# ATmega128 device description
Architecture: AVR8; Family: megaAVR
Registers are 8-bit, access not given, no defined reset value unless marked. A register's access mark holds for its fields unless they carry their own. Offsets are from the block's base; [hi:lo] are bit positions.

## TC1 (TC16 module) — Timer/Counter, 16-bit
Instances: TC1 0x00
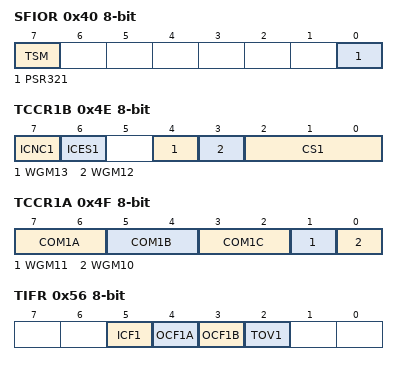
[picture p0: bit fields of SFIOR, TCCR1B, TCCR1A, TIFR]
0x40 SFIOR — Special Function IO Register
  [7] TSM — Timer/Counter Synchronization Mode
  [0] PSR321 — Prescaler Reset, T/C3, T/C2, T/C1
0x46 ICR1 16-bit — Timer/Counter1 Input Capture Register Bytes
0x48 OCR1B 16-bit — Timer/Counter1 Output Compare Register Bytes
0x4A OCR1A 16-bit — Timer/Counter1 Output Compare Register Bytes
0x4C TCNT1 16-bit — Timer/Counter1 Bytes
0x4E TCCR1B — Timer/Counter1 Control Register B
  [7] ICNC1 — Input Capture 1 Noise Canceler
  [6] ICES1 — Input Capture 1 Edge Select
  [4] WGM13 (bit 2 of the value upward) — Waveform Generation Mode
  [3] WGM12 (bit 2 of the value upward) — Waveform Generation Mode
  [2:0] CS1 — Clock Select1 bits
    0=No Clock Source (Stopped); 1=Running, No Prescaling; 2=Running, CLK/8; 3=Running, CLK/64; 4=Running, CLK/256; 5=Running, CLK/1024; 6=Running, ExtClk Tx Falling Edge; 7=Running, ExtClk Tx Rising Edge
0x4F TCCR1A — Timer/Counter1 Control Register A
  [7:6] COM1A — Compare Output Mode 1A, bits
  [5:4] COM1B — Compare Output Mode 1B, bits
  [3:2] COM1C — Compare Output Mode 1C, bits
  [1] WGM11 — Waveform Generation Mode
  [0] WGM10 — Waveform Generation Mode
0x56 TIFR — Timer/Counter Interrupt Flag register
  [5] ICF1 — Input Capture Flag 1
  [4] OCF1A — Output Compare Flag 1A
  [3] OCF1B — Output Compare Flag 1B
  [2] TOV1 — Timer/Counter1 Overflow Flag
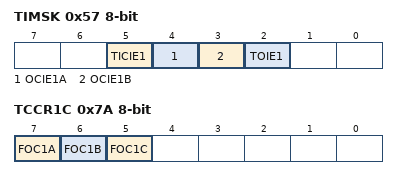
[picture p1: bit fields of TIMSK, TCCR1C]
0x57 TIMSK — Timer/Counter Interrupt Mask Register
  [5] TICIE1 — Timer/Counter1 Input Capture Interrupt Enable
  [4] OCIE1A — Timer/Counter1 Output CompareA Match Interrupt Enable
  [3] OCIE1B — Timer/Counter1 Output CompareB Match Interrupt Enable
  [2] TOIE1 — Timer/Counter1 Overflow Interrupt Enable
0x78 OCR1C 16-bit — Timer/Counter1 Output Compare Register Bytes
0x7A TCCR1C — Timer/Counter1 Control Register C
  [7] FOC1A — Force Output Compare for channel A
  [6] FOC1B — Force Output Compare for channel B
  [5] FOC1C — Force Output Compare for channel C
0x7C ETIFR — Extended Timer/Counter Interrupt Flag register
  [0] OCF1C — Timer/Counter 1, Output Compare C Match Flag
0x7D ETIMSK — Extended Timer/Counter Interrupt Mask Register
  [0] OCIE1C — Timer/Counter 1, Output Compare Match C Interrupt Enable

## TC3 (TC16 module) — Timer/Counter, 16-bit
Instances: TC3 0x00
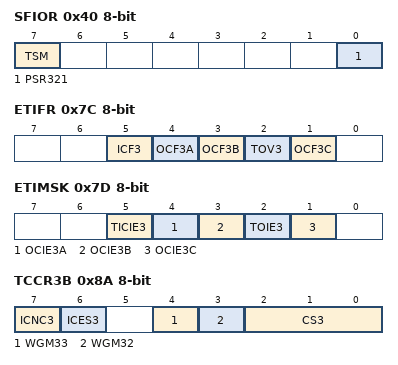
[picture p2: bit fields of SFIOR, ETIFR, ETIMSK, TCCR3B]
0x40 SFIOR — Special Function IO Register
  [7] TSM — Timer/Counter Synchronization Mode
  [0] PSR321 — Prescaler Reset, T/C3, T/C2, T/C1
0x7C ETIFR — Extended Timer/Counter Interrupt Flag register
  [5] ICF3 — Input Capture Flag 3
  [4] OCF3A — Output Compare Flag 3A
  [3] OCF3B — Output Compare Flag 3B
  [2] TOV3 — Timer/Counter3 Overflow Flag
  [1] OCF3C — Timer/Counter3 Output Compare C Match Flag
0x7D ETIMSK — Extended Timer/Counter Interrupt Mask Register
  [5] TICIE3 — Timer/Counter3 Input Capture Interrupt Enable
  [4] OCIE3A — Timer/Counter3 Output CompareA Match Interrupt Enable
  [3] OCIE3B — Timer/Counter3 Output CompareB Match Interrupt Enable
  [2] TOIE3 — Timer/Counter3 Overflow Interrupt Enable
  [1] OCIE3C — Timer/Counter3, Output Compare Match Interrupt Enable
0x80 ICR3 16-bit — Timer/Counter3 Input Capture Register Bytes
0x82 OCR3C 16-bit — Timer/Counter3 Output compare Register C Bytes
0x84 OCR3B 16-bit — Timer/Counter3 Output Compare Register B Bytes
0x86 OCR3A 16-bit — Timer/Counter3 Output Compare Register A Bytes
0x88 TCNT3 16-bit — Timer/Counter3 Bytes
0x8A TCCR3B — Timer/Counter3 Control Register B
  [7] ICNC3 — Input Capture 3 Noise Canceler
  [6] ICES3 — Input Capture 3 Edge Select
  [4] WGM33 (bit 2 of the value upward) — Waveform Generation Mode
  [3] WGM32 (bit 2 of the value upward) — Waveform Generation Mode
  [2:0] CS3 — Clock Select3 bits
    0=No Clock Source (Stopped); 1=Running, No Prescaling; 2=Running, CLK/8; 3=Running, CLK/64; 4=Running, CLK/256; 5=Running, CLK/1024; 6=Running, ExtClk Tx Falling Edge; 7=Running, ExtClk Tx Rising Edge
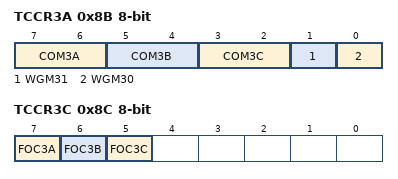
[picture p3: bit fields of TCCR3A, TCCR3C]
0x8B TCCR3A — Timer/Counter3 Control Register A
  [7:6] COM3A — Compare Output Mode 3A, bits
  [5:4] COM3B — Compare Output Mode 3B, bits
  [3:2] COM3C — Compare Output Mode 3C, bits
  [1] WGM31 — Waveform Generation Mode
  [0] WGM30 — Waveform Generation Mode
0x8C TCCR3C — Timer/Counter3 Control Register C
  [7] FOC3A — Force Output Compare for channel A
  [6] FOC3B — Force Output Compare for channel B
  [5] FOC3C — Force Output Compare for channel C

## TC2 (TC8 module) — Timer/Counter, 8-bit
Instances: TC2 0x00
0x43 OCR2 — Output Compare Register
0x44 TCNT2 — Timer/Counter Register
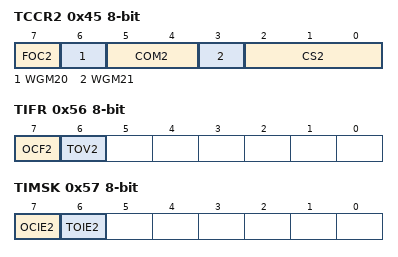
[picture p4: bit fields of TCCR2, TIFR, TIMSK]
0x45 TCCR2 — Timer/Counter Control Register
  [7] FOC2 — Force Output Compare
  [6] WGM20 — Wafeform Generation Mode
    0=Normal; 2=PWM, Phase Correct; 1=CTC; 3=Fast PWM
  [5:4] COM2 — Compare Match Output Mode
  [3] WGM21 — Waveform Generation Mode
  [2:0] CS2 — Clock Select
    0=No Clock Source (Stopped); 1=Running, No Prescaling; 2=Running, CLK/8; 3=Running, CLK/64; 4=Running, CLK/256; 5=Running, CLK/1024; 6=Running, ExtClk Tx Falling Edge; 7=Running, ExtClk Tx Rising Edge
0x56 TIFR — Timer/Counter Interrupt Flag Register
  [7] OCF2 — Output Compare Flag 2
  [6] TOV2 — Timer/Counter2 Overflow Flag
0x57 TIMSK
  [7] OCIE2, [6] TOIE2

## WDT — Watchdog Timer
Instances: WDT 0x00
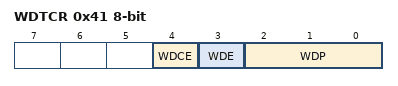
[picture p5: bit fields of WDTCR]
0x41 WDTCR — Watchdog Timer Control Register
  [4] WDCE — Watchdog Change Enable
  [3] WDE — Watch Dog Enable
  [2:0] WDP — Watch Dog Timer Prescaler bits
    0=Oscillator Cycles 16K; 1=Oscillator Cycles 32K; 2=Oscillator Cycles 64K; 3=Oscillator Cycles 128K; 4=Oscillator Cycles 256K; 5=Oscillator Cycles 512K; 6=Oscillator Cycles 1024K; 7=Oscillator Cycles 2048K

## ADC — Analog-to-Digital Converter
Instances: ADC 0x00
0x24 ADC 16-bit — ADC Data Register Bytes
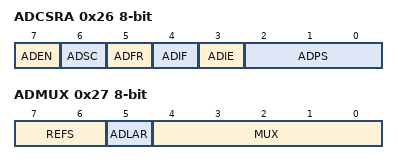
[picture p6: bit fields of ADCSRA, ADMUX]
0x26 ADCSRA — The ADC Control and Status register
  [7] ADEN — ADC Enable
  [6] ADSC — ADC Start Conversion
  [5] ADFR — ADC Free Running Select
  [4] ADIF — ADC Interrupt Flag
  [3] ADIE — ADC Interrupt Enable
  [2:0] ADPS — ADC Prescaler Select Bits
    0=2; 1=2; 2=4; 3=8; 4=16; 5=32; 6=64; 7=128
0x27 ADMUX — The ADC multiplexer Selection Register
  [7:6] REFS — Reference Selection Bits
    0=AREF, Internal Vref turned off; 1=AVCC with external capacitor at AREF pin; 3=Internal 2.56V Voltage Reference with external capacitor at AREF pin
  [5] ADLAR — Left Adjust Result
  [4:0] MUX — Analog Channel and Gain Selection Bits
